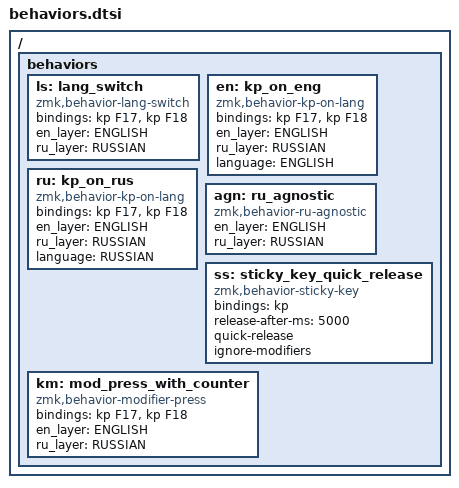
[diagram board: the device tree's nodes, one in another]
/ {
    behaviors {
        // переключение языка
        // аргумент -- номер слоя раскладки
        //             если аргумент не равен номеру слоя раскладки
        //             переключение производится на другую раскладку (не равную текущей)
        ls: lang_switch {
            compatible = "zmk,behavior-lang-switch";
            #binding-cells = <1>;
            // Коды клавиш  F17-переключение на EN F18 = переключение на RU
            bindings = <&kp F17>, <&kp F18>;
            en_layer = <ENGLISH>;
            ru_layer = <RUSSIAN>;
        };

        // нажатие символа принудительно в английской раскладке
        en: kp_on_eng {
            compatible = "zmk,behavior-kp-on-lang";
            #binding-cells = <1>;
            bindings = <&kp F17>, <&kp F18>;
            en_layer = <ENGLISH>;
            ru_layer = <RUSSIAN>;
            language = <ENGLISH>;
        };

        // нажатие символа принудительно в русской раскладке
        ru: kp_on_rus {
            compatible = "zmk,behavior-kp-on-lang";
            #binding-cells = <1>;
            bindings = <&kp F17>, <&kp F18>;
            en_layer = <ENGLISH>;
            ru_layer = <RUSSIAN>;
            language = <RUSSIAN>;
        };

        // разобраться, где на клавиатуре этот символ в зависимости от текущей раскладки
        // и нажать его именно там, без переключения раскладки в системе
        // использовать только для символов которые переезжают на другую клавишу
        // в русской раскладке, типа ".", "?" и т.д.
        agn: ru_agnostic {
            compatible = "zmk,behavior-ru-agnostic";
            #binding-cells = <1>;
            en_layer = <ENGLISH>;
            ru_layer = <RUSSIAN>;
        };

        // залипание -- если была нажата и быстро отпущена клавиша -- используется для shift
        ss: sticky_key_quick_release {
            compatible = "zmk,behavior-sticky-key";
            #binding-cells = <1>;
            bindings = <&kp>;
            release-after-ms = <5000>;
            quick-release;
            ignore-modifiers;
        };

        // использовать вместо &kp для модификаторов которые при удерживании должны работать только с английской раскладкой
        km: mod_press_with_counter {
            compatible = "zmk,behavior-modifier-press";
            #binding-cells = <1>;
            // Коды клавиш  F17-переключение на EN F18 = переключение на RU
            bindings = <&kp F17>, <&kp F18>;
            en_layer = <ENGLISH>;
            ru_layer = <RUSSIAN>;
        };
    };
};
